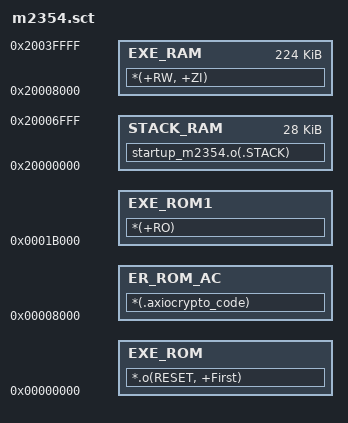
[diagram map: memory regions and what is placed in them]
#! armclang --target=arm-arm-none-eabi -march=armv8-m.base -E -xc
#define SCATTER_FILE


LR_ROM_AC 0x00008000 0x00013000
{
    ER_ROM_AC +0 
    {
        *(.axiocrypto_code)
    }
}

LR_ROM 0x00000000 0x1000
{

    EXE_ROM +0
    {
        *.o(RESET, +First)
		
    }
	STACK_RAM 0x20000000 0x7000
    {
        startup_m2354.o(.STACK)
    }
}


LR_ROM1 0x0001B000 0xE5000
{

    EXE_ROM1 +0
    {
        *(+RO)
    }
    
    EXE_RAM 0x20008000 0x38000
    {
        *(+RW, +ZI)
    }
  
}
